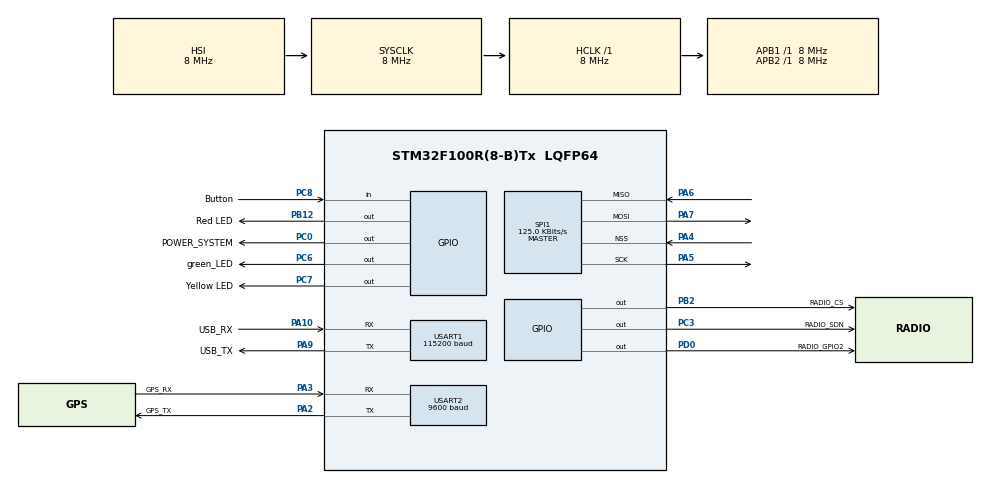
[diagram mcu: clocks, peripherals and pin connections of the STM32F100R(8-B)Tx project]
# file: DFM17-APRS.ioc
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Mcu.Family=STM32F1
Mcu.Name=STM32F100R(8-B)Tx
Mcu.Package=LQFP64
NVIC.PriorityGroup=NVIC_PRIORITYGROUP_4
PA10.GPIO_Label=USB_RX
PA10.Mode=Asynchronous
PA10.Signal=USART1_RX
PA13.Mode=Serial_Wire
PA13.Signal=SYS_JTMS-SWDIO
PA14.Mode=Serial_Wire
PA14.Signal=SYS_JTCK-SWCLK
PA2.GPIO_Label=GPS_TX
PA2.Mode=Asynchronous
PA2.Signal=USART2_TX
PA3.GPIO_Label=GPS_RX
PA3.Mode=Asynchronous
PA3.Signal=USART2_RX
PA4.Mode=NSS_Signal_Hard_Input
PA4.Signal=SPI1_NSS
PA5.Mode=Full_Duplex_Master
PA5.Signal=SPI1_SCK
PA6.Mode=Full_Duplex_Master
PA6.Signal=SPI1_MISO
PA7.Mode=Full_Duplex_Master
PA7.Signal=SPI1_MOSI
PA9.GPIO_Label=USB_TX
PA9.Mode=Asynchronous
PA9.Signal=USART1_TX
PB12.GPIO_Label=Red LED
PB12.PinState=GPIO_PIN_SET
PB12.Signal=GPIO_Output
PB2.GPIO_Label=RADIO_CS
PB2.Signal=GPIO_Output
PC0.GPIO_Label=POWER_SYSTEM
PC0.PinState=GPIO_PIN_SET
PC0.Signal=GPIO_Output
PC3.GPIO_Label=RADIO_SDN
PC3.Signal=GPIO_Output
PC6.GPIO_Label=green_LED
PC6.Signal=GPIO_Output
PC7.GPIO_Label=Yellow LED
PC7.Signal=GPIO_Output
PC8.GPIO_Label=Button
PC8.Signal=GPIO_Input
PD0-OSC_IN.GPIO_Label=RADIO_GPIO2
PD0-OSC_IN.Signal=GPIO_Output
ProjectManager.HeapSize=0x200
ProjectManager.StackSize=0x400
ProjectManager.TargetToolchain=STM32CubeIDE
RCC.AHBFreq_Value=8000000
RCC.APB1Freq_Value=8000000
RCC.APB1TimFreq_Value=8000000
RCC.APB2Freq_Value=8000000
RCC.APB2TimFreq_Value=8000000
RCC.HCLKFreq_Value=8000000
RCC.SYSCLKFreq_VALUE=8000000
SPI1.BaudRatePrescaler=SPI_BAUDRATEPRESCALER_64
SPI1.CalculateBaudRate=125.0 KBits/s
SPI1.Direction=SPI_DIRECTION_2LINES
SPI1.Mode=SPI_MODE_MASTER
SPI1.VirtualNSS=VM_NSSHARD
SPI1.VirtualType=VM_MASTER
USART1.BaudRate=115200
USART1.VirtualMode=VM_ASYNC
USART2.BaudRate=9600
USART2.VirtualMode=VM_ASYNC
board=custom

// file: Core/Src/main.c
/* USER CODE BEGIN Header */
/**
  ******************************************************************************
  * @file           : main.c
  * @brief          : Main program body
  ******************************************************************************
  * @attention
  *
  * <h2><center>&copy; Copyright (c) 2021 STMicroelectronics.
  * All rights reserved.</center></h2>
  *
  * This software component is licensed by ST under BSD 3-Clause license,
  * the "License"; You may not use this file except in compliance with the
  * License. You may obtain a copy of the License at:
  *                        opensource.org/licenses/BSD-3-Clause
  *
  ******************************************************************************
  */
/* USER CODE END Header */
#include "main.h"

/* USER CODE BEGIN PTD */
uint8_t UART1_rxBuffer[1024] = {0};
/* USER CODE END PTD */

 SPI_HandleTypeDef hspi1;

UART_HandleTypeDef huart1;
UART_HandleTypeDef huart2;

void SystemClock_Config(void);
static void MX_GPIO_Init(void);
static void MX_USART1_UART_Init(void);
static void MX_USART2_UART_Init(void);
static void MX_SPI1_Init(void);

int main(void)
{

  /* MCU Configuration--------------------------------------------------------*/

  /* Reset of all peripherals, Initializes the Flash interface and the Systick. */
  HAL_Init();

  /* Configure the system clock */
  SystemClock_Config();

  /* Initialize all configured peripherals */
  MX_GPIO_Init();
  MX_USART1_UART_Init();
  MX_USART2_UART_Init();
  MX_SPI1_Init();
  /* USER CODE BEGIN 2 */
  int led_num = 0;

  HAL_GPIO_WritePin(GPIOC, green_LED_Pin, GPIO_PIN_SET);
  SI4063_init(25000000, 0, &hspi1);
  SI4063_set_PA_mode(2, 0);
  SI4063_set_power_level(20);
  SI4063_change_state(1);
  /* USER CODE END 2 */

  /* Infinite loop */
  /* USER CODE BEGIN WHILE */
  while (1)
  {
	  HAL_GPIO_WritePin(GPIOC, Yellow_LED_Pin, GPIO_PIN_SET);
	  SI4063_tx_CW_blips(5, 500, 434200000, 16369000, 0);
	  HAL_GPIO_WritePin(GPIOC, Yellow_LED_Pin, GPIO_PIN_RESET);
	  HAL_Delay(2000);
    /* USER CODE END WHILE */

  }
}

void SystemClock_Config(void)
{
  RCC_OscInitTypeDef RCC_OscInitStruct = {0};
  RCC_ClkInitTypeDef RCC_ClkInitStruct = {0};

  /** Initializes the RCC Oscillators according to the specified parameters
  * in the RCC_OscInitTypeDef structure.
  */
  RCC_OscInitStruct.OscillatorType = RCC_OSCILLATORTYPE_HSI;
  RCC_OscInitStruct.HSIState = RCC_HSI_ON;
  RCC_OscInitStruct.HSICalibrationValue = RCC_HSICALIBRATION_DEFAULT;
  RCC_OscInitStruct.PLL.PLLState = RCC_PLL_NONE;
  if (HAL_RCC_OscConfig(&RCC_OscInitStruct) != HAL_OK)
  {
    Error_Handler();
  }

  /** Initializes the CPU, AHB and APB buses clocks
  */
  RCC_ClkInitStruct.ClockType = RCC_CLOCKTYPE_HCLK|RCC_CLOCKTYPE_SYSCLK
                              |RCC_CLOCKTYPE_PCLK1|RCC_CLOCKTYPE_PCLK2;
  RCC_ClkInitStruct.SYSCLKSource = RCC_SYSCLKSOURCE_HSI;
  RCC_ClkInitStruct.AHBCLKDivider = RCC_SYSCLK_DIV1;
  RCC_ClkInitStruct.APB1CLKDivider = RCC_HCLK_DIV1;
  RCC_ClkInitStruct.APB2CLKDivider = RCC_HCLK_DIV1;

  if (HAL_RCC_ClockConfig(&RCC_ClkInitStruct, FLASH_LATENCY_0) != HAL_OK)
  {
    Error_Handler();
  }
}

static void MX_SPI1_Init(void)
{

  /* SPI1 parameter configuration*/
  hspi1.Instance = SPI1;
  hspi1.Init.Mode = SPI_MODE_MASTER;
  hspi1.Init.Direction = SPI_DIRECTION_2LINES;
  hspi1.Init.DataSize = SPI_DATASIZE_8BIT;
  hspi1.Init.CLKPolarity = SPI_POLARITY_LOW;
  hspi1.Init.CLKPhase = SPI_PHASE_1EDGE;
  hspi1.Init.NSS = SPI_NSS_HARD_INPUT;
  hspi1.Init.BaudRatePrescaler = SPI_BAUDRATEPRESCALER_64;
  hspi1.Init.FirstBit = SPI_FIRSTBIT_MSB;
  hspi1.Init.TIMode = SPI_TIMODE_DISABLE;
  hspi1.Init.CRCCalculation = SPI_CRCCALCULATION_DISABLE;
  hspi1.Init.CRCPolynomial = 10;
  if (HAL_SPI_Init(&hspi1) != HAL_OK)
  {
    Error_Handler();
  }

}

static void MX_USART1_UART_Init(void)
{

  huart1.Instance = USART1;
  huart1.Init.BaudRate = 115200;
  huart1.Init.WordLength = UART_WORDLENGTH_8B;
  huart1.Init.StopBits = UART_STOPBITS_1;
  huart1.Init.Parity = UART_PARITY_NONE;
  huart1.Init.Mode = UART_MODE_TX_RX;
  huart1.Init.HwFlowCtl = UART_HWCONTROL_NONE;
  huart1.Init.OverSampling = UART_OVERSAMPLING_16;
  if (HAL_UART_Init(&huart1) != HAL_OK)
  {
    Error_Handler();
  }

}

static void MX_USART2_UART_Init(void)
{

  huart2.Instance = USART2;
  huart2.Init.BaudRate = 9600;
  huart2.Init.WordLength = UART_WORDLENGTH_8B;
  huart2.Init.StopBits = UART_STOPBITS_1;
  huart2.Init.Parity = UART_PARITY_NONE;
  huart2.Init.Mode = UART_MODE_TX_RX;
  huart2.Init.HwFlowCtl = UART_HWCONTROL_NONE;
  huart2.Init.OverSampling = UART_OVERSAMPLING_16;
  if (HAL_UART_Init(&huart2) != HAL_OK)
  {
    Error_Handler();
  }

}

static void MX_GPIO_Init(void)
{
  GPIO_InitTypeDef GPIO_InitStruct = {0};

  /* GPIO Ports Clock Enable */
  __HAL_RCC_GPIOD_CLK_ENABLE();
  __HAL_RCC_GPIOC_CLK_ENABLE();
  __HAL_RCC_GPIOA_CLK_ENABLE();
  __HAL_RCC_GPIOB_CLK_ENABLE();

  /*Configure GPIO pin Output Level */
  HAL_GPIO_WritePin(RADIO_GPIO2_GPIO_Port, RADIO_GPIO2_Pin, GPIO_PIN_RESET);

  /*Configure GPIO pin Output Level */
  HAL_GPIO_WritePin(POWER_SYSTEM_GPIO_Port, POWER_SYSTEM_Pin, GPIO_PIN_SET);

  /*Configure GPIO pin Output Level */
  HAL_GPIO_WritePin(GPIOC, RADIO_SDN_Pin|green_LED_Pin|Yellow_LED_Pin, GPIO_PIN_RESET);

  /*Configure GPIO pin Output Level */
  HAL_GPIO_WritePin(RADIO_CS_GPIO_Port, RADIO_CS_Pin, GPIO_PIN_RESET);

  /*Configure GPIO pin Output Level */
  HAL_GPIO_WritePin(Red_LED_GPIO_Port, Red_LED_Pin, GPIO_PIN_SET);

  /*Configure GPIO pin : RADIO_GPIO2_Pin */
  GPIO_InitStruct.Pin = RADIO_GPIO2_Pin;
  GPIO_InitStruct.Mode = GPIO_MODE_OUTPUT_PP;
  GPIO_InitStruct.Pull = GPIO_NOPULL;
  GPIO_InitStruct.Speed = GPIO_SPEED_FREQ_LOW;
  HAL_GPIO_Init(RADIO_GPIO2_GPIO_Port, &GPIO_InitStruct);

  /*Configure GPIO pins : POWER_SYSTEM_Pin RADIO_SDN_Pin green_LED_Pin Yellow_LED_Pin */
  GPIO_InitStruct.Pin = POWER_SYSTEM_Pin|RADIO_SDN_Pin|green_LED_Pin|Yellow_LED_Pin;
  GPIO_InitStruct.Mode = GPIO_MODE_OUTPUT_PP;
  GPIO_InitStruct.Pull = GPIO_NOPULL;
  GPIO_InitStruct.Speed = GPIO_SPEED_FREQ_LOW;
  HAL_GPIO_Init(GPIOC, &GPIO_InitStruct);

  /*Configure GPIO pins : RADIO_CS_Pin Red_LED_Pin */
  GPIO_InitStruct.Pin = RADIO_CS_Pin|Red_LED_Pin;
  GPIO_InitStruct.Mode = GPIO_MODE_OUTPUT_PP;
  GPIO_InitStruct.Pull = GPIO_NOPULL;
  GPIO_InitStruct.Speed = GPIO_SPEED_FREQ_LOW;
  HAL_GPIO_Init(GPIOB, &GPIO_InitStruct);

  /*Configure GPIO pin : Button_Pin */
  GPIO_InitStruct.Pin = Button_Pin;
  GPIO_InitStruct.Mode = GPIO_MODE_INPUT;
  GPIO_InitStruct.Pull = GPIO_NOPULL;
  HAL_GPIO_Init(Button_GPIO_Port, &GPIO_InitStruct);

  /*Configure peripheral I/O remapping */
  __HAL_AFIO_REMAP_PD01_ENABLE();

}

void Error_Handler(void)
{
  /* USER CODE BEGIN Error_Handler_Debug */
  /* User can add his own implementation to report the HAL error return state */
  HAL_GPIO_WritePin(GPIOC, green_LED_Pin, GPIO_PIN_RESET);
  __disable_irq();
  while (1)
  {
  }
  /* USER CODE END Error_Handler_Debug */
}
